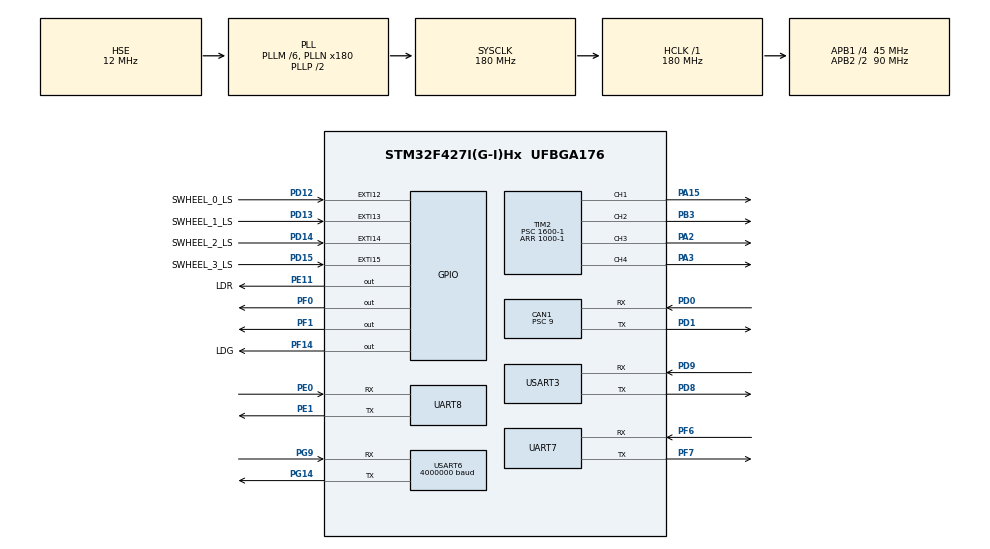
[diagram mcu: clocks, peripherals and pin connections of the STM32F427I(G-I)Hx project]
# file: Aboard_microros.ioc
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CAN1.ABOM=DISABLE
CAN1.AWUM=DISABLE
CAN1.BS1=CAN_BS1_3TQ
CAN1.BS2=CAN_BS2_1TQ
CAN1.CalculateBaudRate=1000000
CAN1.CalculateTimeBit=1000
CAN1.CalculateTimeQuantum=200.0
CAN1.Mode=CAN_MODE_NORMAL
CAN1.NART=DISABLE
CAN1.Prescaler=9
CAN1.RFLM=DISABLE
CAN1.SJW=CAN_SJW_1TQ
CAN1.TTCM=DISABLE
CAN1.TXFP=DISABLE
Dma.Request0=USART6_RX
Dma.Request1=USART6_TX
Dma.USART6_RX.0.Direction=DMA_PERIPH_TO_MEMORY
Dma.USART6_RX.0.FIFOMode=DMA_FIFOMODE_DISABLE
Dma.USART6_RX.0.Instance=DMA2_Stream1
Dma.USART6_RX.0.MemDataAlignment=DMA_MDATAALIGN_BYTE
Dma.USART6_RX.0.MemInc=DMA_MINC_ENABLE
Dma.USART6_RX.0.Mode=DMA_CIRCULAR
Dma.USART6_RX.0.PeriphDataAlignment=DMA_PDATAALIGN_BYTE
Dma.USART6_RX.0.PeriphInc=DMA_PINC_DISABLE
Dma.USART6_RX.0.Priority=DMA_PRIORITY_VERY_HIGH
Dma.USART6_TX.1.Direction=DMA_MEMORY_TO_PERIPH
Dma.USART6_TX.1.FIFOMode=DMA_FIFOMODE_DISABLE
Dma.USART6_TX.1.Instance=DMA2_Stream6
Dma.USART6_TX.1.MemDataAlignment=DMA_MDATAALIGN_BYTE
Dma.USART6_TX.1.MemInc=DMA_MINC_ENABLE
Dma.USART6_TX.1.Mode=DMA_NORMAL
Dma.USART6_TX.1.PeriphDataAlignment=DMA_PDATAALIGN_BYTE
Dma.USART6_TX.1.PeriphInc=DMA_PINC_DISABLE
Dma.USART6_TX.1.Priority=DMA_PRIORITY_VERY_HIGH
FREERTOS.Tasks01=MavlinkTask,24,512,StartMavlinkTask,As weak,NULL,Dynamic,NULL,NULL;upControlTask,24,512,StartUpControlTask,As weak,NULL,Dynamic,NULL,NULL;chassisTask,8,512,StartChassisTask,As weak,NULL,Dynamic,NULL,NULL
FREERTOS.configENABLE_FPU=1
FREERTOS.configUSE_NEWLIB_REENTRANT=1
Mcu.Family=STM32F4
Mcu.Name=STM32F427I(G-I)Hx
Mcu.Package=UFBGA176
NVIC.CAN1_RX0_IRQn=true\:5\:0\:false\:false\:true\:true\:true\:true\:true
NVIC.DMA2_Stream1_IRQn=true\:5\:0\:false\:false\:true\:true\:false\:true\:true
NVIC.DMA2_Stream6_IRQn=true\:5\:0\:false\:false\:true\:true\:false\:true\:true
NVIC.EXTI15_10_IRQn=true\:5\:0\:true\:false\:true\:true\:true\:true\:true
NVIC.PriorityGroup=NVIC_PRIORITYGROUP_4
NVIC.TIM1_UP_TIM10_IRQn=true\:15\:0\:false\:false\:true\:false\:false\:true\:true
NVIC.TimeBase=TIM1_UP_TIM10_IRQn
NVIC.TimeBaseIP=TIM1
NVIC.UART8_IRQn=true\:5\:0\:false\:false\:true\:true\:true\:true\:true
NVIC.USART3_IRQn=true\:5\:0\:false\:false\:true\:true\:true\:true\:true
NVIC.USART6_IRQn=true\:5\:0\:false\:false\:true\:true\:true\:true\:true
PA13.Mode=Serial_Wire
PA13.Signal=SYS_JTMS-SWDIO
PA14.Mode=Serial_Wire
PA14.Signal=SYS_JTCK-SWCLK
PA15.Signal=S_TIM2_CH1_ETR
PA2.Signal=S_TIM2_CH3
PA3.Signal=S_TIM2_CH4
PB3.Signal=S_TIM2_CH2
PC14/OSC32_IN.Mode=LSE-External-Clock-Source
PC14/OSC32_IN.Signal=RCC_OSC32_IN
PC15/OSC32_OUT.Mode=LSE-External-Clock-Source
PC15/OSC32_OUT.Signal=RCC_OSC32_OUT
PD0.Mode=CAN_Activate
PD0.Signal=CAN1_RX
PD1.Mode=CAN_Activate
PD1.Signal=CAN1_TX
PD12.GPIO_Label=SWHEEL_0_LS
PD12.GPIO_PuPd=GPIO_PULLDOWN
PD12.Signal=GPXTI12
PD13.GPIO_Label=SWHEEL_1_LS
PD13.GPIO_PuPd=GPIO_PULLDOWN
PD13.Signal=GPXTI13
PD14.GPIO_Label=SWHEEL_2_LS
PD14.GPIO_PuPd=GPIO_PULLDOWN
PD14.Signal=GPXTI14
PD15.GPIO_Label=SWHEEL_3_LS
PD15.GPIO_PuPd=GPIO_PULLDOWN
PD15.Signal=GPXTI15
PD8.Mode=Asynchronous
PD8.Signal=USART3_TX
PD9.Mode=Asynchronous
PD9.Signal=USART3_RX
PE0.Mode=Asynchronous
PE0.Signal=UART8_RX
PE1.Mode=Asynchronous
PE1.Signal=UART8_TX
PE11.GPIO_Label=LDR
PE11.PinState=GPIO_PIN_SET
PE11.Signal=GPIO_Output
PF0.Signal=GPIO_Output
PF1.Signal=GPIO_Output
PF14.GPIO_Label=LDG
PF14.PinState=GPIO_PIN_SET
PF14.Signal=GPIO_Output
PF6.Mode=Asynchronous
PF6.Signal=UART7_RX
PF7.Mode=Asynchronous
PF7.Signal=UART7_TX
PG14.Mode=Asynchronous
PG14.Signal=USART6_TX
PG9.Mode=Asynchronous
PG9.Signal=USART6_RX
PH0/OSC_IN.Mode=HSE-External-Oscillator
PH0/OSC_IN.Signal=RCC_OSC_IN
PH1/OSC_OUT.Mode=HSE-External-Oscillator
PH1/OSC_OUT.Signal=RCC_OSC_OUT
ProjectManager.HeapSize=0x200
ProjectManager.StackSize=0x400
ProjectManager.TargetToolchain=Makefile
RCC.48MHZClocksFreq_Value=51428571.428571425
RCC.AHBFreq_Value=180000000
RCC.APB1CLKDivider=RCC_HCLK_DIV4
RCC.APB1Freq_Value=45000000
RCC.APB1TimFreq_Value=90000000
RCC.APB2CLKDivider=RCC_HCLK_DIV2
RCC.APB2Freq_Value=90000000
RCC.APB2TimFreq_Value=180000000
RCC.CortexFreq_Value=180000000
RCC.FLatency=FLASH_LATENCY_5
RCC.HCLKFreq_Value=180000000
RCC.HSE_VALUE=12000000
RCC.HSI_VALUE=16000000
RCC.LSE_VALUE=32768
RCC.PLLM=6
RCC.PLLN=180
RCC.PLLQ=7
RCC.PLLSourceVirtual=RCC_PLLSOURCE_HSE
RCC.PWREXT_OverDrive=PWREXT_OverDrive_ACTIVATED
RCC.PWR_Regulator_Voltage_Scale=PWR_REGULATOR_VOLTAGE_SCALE1
RCC.SYSCLKFreq_VALUE=180000000
RCC.SYSCLKSource=RCC_SYSCLKSOURCE_PLLCLK
RCC.VCOOutputFreq_Value=360000000
SH.S_TIM2_CH1_ETR.0=TIM2_CH1,PWM Generation1 CH1
SH.S_TIM2_CH2.0=TIM2_CH2,PWM Generation2 CH2
SH.S_TIM2_CH3.0=TIM2_CH3,PWM Generation3 CH3
SH.S_TIM2_CH4.0=TIM2_CH4,PWM Generation4 CH4
STMicroelectronics.X-CUBE-ALGOBUILD.1.3.0.LibraryCcDSPOoLibraryJjDSPOoLibrary=true
TIM2.Channel-PWM\ Generation1\ CH1=TIM_CHANNEL_1
TIM2.Channel-PWM\ Generation2\ CH2=TIM_CHANNEL_2
TIM2.Channel-PWM\ Generation3\ CH3=TIM_CHANNEL_3
TIM2.Channel-PWM\ Generation4\ CH4=TIM_CHANNEL_4
TIM2.Period=1000-1
TIM2.Prescaler=1600-1
UART7.VirtualMode=Asynchronous
UART8.VirtualMode=Asynchronous
USART3.VirtualMode=VM_ASYNC
USART6.BaudRate=4000000
USART6.VirtualMode=VM_ASYNC
VP_FREERTOS_VS_CMSIS_V2.Mode=CMSIS_V2
VP_STMicroelectronics.X-CUBE-ALGOBUILD_VS_DSPOoLibraryJjLibrary_1.3.0_1.3.0.Mode=DSPOoLibraryJjLibrary
VP_SYS_VS_tim1.Mode=TIM1
VP_TIM2_VS_ClockSourceINT.Mode=Internal
board=custom

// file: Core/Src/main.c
/* USER CODE BEGIN Header */
/**
  ******************************************************************************
  * @file           : main.c
  * @brief          : Main program body
  ******************************************************************************
  * @attention
  *
  * Copyright (c) 2023 STMicroelectronics.
  * All rights reserved.
  *
  * This software is licensed under terms that can be found in the LICENSE file
  * in the root directory of this software component.
  * If no LICENSE file comes with this software, it is provided AS-IS.
  *
  ******************************************************************************
  */
/* USER CODE END Header */
#include "main.h"
#include "cmsis_os.h"
#include "can.h"
#include "dma.h"
#include "tim.h"
#include "usart.h"
#include "gpio.h"

/* USER CODE BEGIN Includes */
#include "arm_math.h"
/* USER CODE END Includes */

void SystemClock_Config(void);
void MX_FREERTOS_Init(void);

int main(void)
{

  /* MCU Configuration--------------------------------------------------------*/

  /* Reset of all peripherals, Initializes the Flash interface and the Systick. */
  HAL_Init();

  /* Configure the system clock */
  SystemClock_Config();

  /* Initialize all configured peripherals */
  MX_GPIO_Init();
  MX_DMA_Init();
  MX_CAN1_Init();
  MX_USART6_UART_Init();
  MX_TIM2_Init();
  MX_UART8_Init();
  MX_UART7_Init();
  MX_USART3_UART_Init();

  /* Init scheduler */
  osKernelInitialize();  /* Call init function for freertos objects (in freertos.c) */
  MX_FREERTOS_Init();

  /* Start scheduler */
  osKernelStart();

  /* We should never get here as control is now taken by the scheduler */
  /* Infinite loop */
  while (1)
  {

    /* USER CODE BEGIN 3 */
    float32_t pi = PI;
    HAL_GPIO_TogglePin(LDG_GPIO_Port,LDG_Pin);
    HAL_Delay(300);
  }
  /* USER CODE END 3 */
}

void SystemClock_Config(void)
{
  RCC_OscInitTypeDef RCC_OscInitStruct = {0};
  RCC_ClkInitTypeDef RCC_ClkInitStruct = {0};

  /** Configure the main internal regulator output voltage
  */
  __HAL_RCC_PWR_CLK_ENABLE();
  __HAL_PWR_VOLTAGESCALING_CONFIG(PWR_REGULATOR_VOLTAGE_SCALE1);

  /** Initializes the RCC Oscillators according to the specified parameters
  * in the RCC_OscInitTypeDef structure.
  */
  RCC_OscInitStruct.OscillatorType = RCC_OSCILLATORTYPE_HSE;
  RCC_OscInitStruct.HSEState = RCC_HSE_ON;
  RCC_OscInitStruct.PLL.PLLState = RCC_PLL_ON;
  RCC_OscInitStruct.PLL.PLLSource = RCC_PLLSOURCE_HSE;
  RCC_OscInitStruct.PLL.PLLM = 6;
  RCC_OscInitStruct.PLL.PLLN = 180;
  RCC_OscInitStruct.PLL.PLLP = RCC_PLLP_DIV2;
  RCC_OscInitStruct.PLL.PLLQ = 7;
  if (HAL_RCC_OscConfig(&RCC_OscInitStruct) != HAL_OK)
  {
    Error_Handler();
  }

  /** Activate the Over-Drive mode
  */
  if (HAL_PWREx_EnableOverDrive() != HAL_OK)
  {
    Error_Handler();
  }

  /** Initializes the CPU, AHB and APB buses clocks
  */
  RCC_ClkInitStruct.ClockType = RCC_CLOCKTYPE_HCLK|RCC_CLOCKTYPE_SYSCLK
                              |RCC_CLOCKTYPE_PCLK1|RCC_CLOCKTYPE_PCLK2;
  RCC_ClkInitStruct.SYSCLKSource = RCC_SYSCLKSOURCE_PLLCLK;
  RCC_ClkInitStruct.AHBCLKDivider = RCC_SYSCLK_DIV1;
  RCC_ClkInitStruct.APB1CLKDivider = RCC_HCLK_DIV4;
  RCC_ClkInitStruct.APB2CLKDivider = RCC_HCLK_DIV2;

  if (HAL_RCC_ClockConfig(&RCC_ClkInitStruct, FLASH_LATENCY_5) != HAL_OK)
  {
    Error_Handler();
  }
}

void HAL_TIM_PeriodElapsedCallback(TIM_HandleTypeDef *htim)
{
  if (htim->Instance == TIM1) {
    HAL_IncTick();
  }
}

void Error_Handler(void)
{
  __disable_irq();
  while (1)
  {
  }
}

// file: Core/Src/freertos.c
/* USER CODE BEGIN Header */
/**
  ******************************************************************************
  * File Name          : freertos.c
  * Description        : Code for freertos applications
  ******************************************************************************
  * @attention
  *
  * Copyright (c) 2023 STMicroelectronics.
  * All rights reserved.
  *
  * This software is licensed under terms that can be found in the LICENSE file
  * in the root directory of this software component.
  * If no LICENSE file comes with this software, it is provided AS-IS.
  *
  ******************************************************************************
  */
/* USER CODE END Header */

#include "FreeRTOS.h"
#include "task.h"
#include "main.h"
#include "cmsis_os.h"

/* Definitions for MavlinkTask */
osThreadId_t MavlinkTaskHandle;
const osThreadAttr_t MavlinkTask_attributes = {
  .name = "MavlinkTask",
  .stack_size = 512 * 4,
  .priority = (osPriority_t) osPriorityNormal,
};
/* Definitions for upControlTask */
osThreadId_t upControlTaskHandle;
const osThreadAttr_t upControlTask_attributes = {
  .name = "upControlTask",
  .stack_size = 512 * 4,
  .priority = (osPriority_t) osPriorityNormal,
};
/* Definitions for chassisTask */
osThreadId_t chassisTaskHandle;
const osThreadAttr_t chassisTask_attributes = {
  .name = "chassisTask",
  .stack_size = 512 * 4,
  .priority = (osPriority_t) osPriorityLow,
};

void StartMavlinkTask(void *argument);
void StartUpControlTask(void *argument);
void StartChassisTask(void *argument);

void MX_FREERTOS_Init(void); /* (MISRA C 2004 rule 8.1) */

void MX_FREERTOS_Init(void) {

  /* Create the thread(s) */
  /* creation of MavlinkTask */
  MavlinkTaskHandle = osThreadNew(StartMavlinkTask, NULL, &MavlinkTask_attributes);

  /* creation of upControlTask */
  upControlTaskHandle = osThreadNew(StartUpControlTask, NULL, &upControlTask_attributes);

  /* creation of chassisTask */
  chassisTaskHandle = osThreadNew(StartChassisTask, NULL, &chassisTask_attributes);

}

__weak void StartMavlinkTask(void *argument)
{
  for(;;)
  {
    osDelay(1);
  }
}

__weak void StartUpControlTask(void *argument)
{
  for(;;)
  {
    osDelay(1);
  }
}

__weak void StartChassisTask(void *argument)
{
  for(;;)
  {
    osDelay(1);
  }
}
